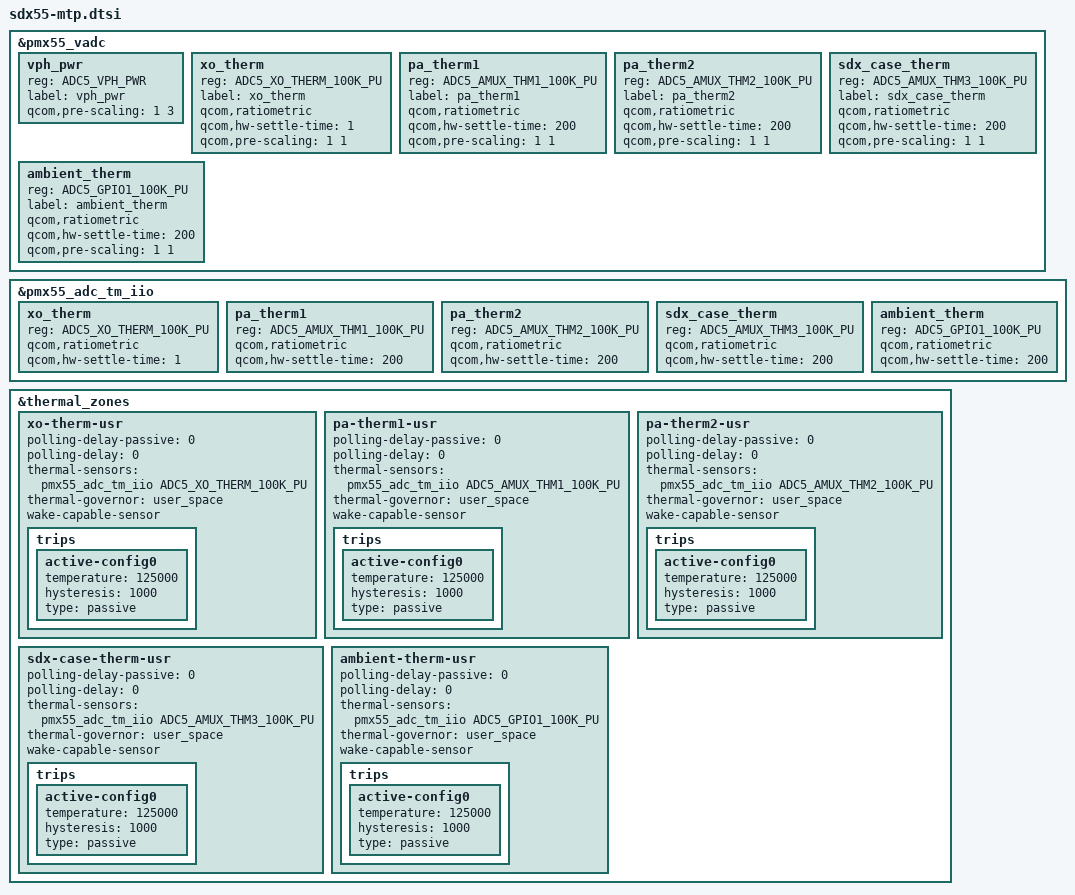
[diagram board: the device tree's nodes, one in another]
#include "sdx55-pmic-overlay.dtsi"
#include "sa515m-mtp-audio-overlay.dtsi"

&pmx55_vadc {
	vph_pwr {
		reg = <ADC5_VPH_PWR>;
		label = "vph_pwr";
		qcom,pre-scaling = <1 3>;
	};

	xo_therm {
		reg = <ADC5_XO_THERM_100K_PU>;
		label = "xo_therm";
		qcom,ratiometric;
		qcom,hw-settle-time = <1>;
		qcom,pre-scaling = <1 1>;
	};

	pa_therm1 {
		reg = <ADC5_AMUX_THM1_100K_PU>;
		label = "pa_therm1";
		qcom,ratiometric;
		qcom,hw-settle-time = <200>;
		qcom,pre-scaling = <1 1>;
	};

	pa_therm2 {
		reg = <ADC5_AMUX_THM2_100K_PU>;
		label = "pa_therm2";
		qcom,ratiometric;
		qcom,hw-settle-time = <200>;
		qcom,pre-scaling = <1 1>;
	};

	sdx_case_therm {
		reg = <ADC5_AMUX_THM3_100K_PU>;
		label = "sdx_case_therm";
		qcom,ratiometric;
		qcom,hw-settle-time = <200>;
		qcom,pre-scaling = <1 1>;
	};

	ambient_therm {
		reg = <ADC5_GPIO1_100K_PU>;
		label = "ambient_therm";
		qcom,ratiometric;
		qcom,hw-settle-time = <200>;
		qcom,pre-scaling = <1 1>;
	};
};

&pmx55_adc_tm_iio {
	xo_therm {
		reg = <ADC5_XO_THERM_100K_PU>;
		qcom,ratiometric;
		qcom,hw-settle-time = <1>;
	};

	pa_therm1 {
		reg = <ADC5_AMUX_THM1_100K_PU>;
		qcom,ratiometric;
		qcom,hw-settle-time = <200>;
	};

	pa_therm2 {
		reg = <ADC5_AMUX_THM2_100K_PU>;
		qcom,ratiometric;
		qcom,hw-settle-time = <200>;
	};

	sdx_case_therm {
		reg = <ADC5_AMUX_THM3_100K_PU>;
		qcom,ratiometric;
		qcom,hw-settle-time = <200>;
	};

	ambient_therm {
		reg = <ADC5_GPIO1_100K_PU>;
		qcom,ratiometric;
		qcom,hw-settle-time = <200>;
	};
};

&thermal_zones {
	xo-therm-usr {
		polling-delay-passive = <0>;
		polling-delay = <0>;
		thermal-sensors = <&pmx55_adc_tm_iio ADC5_XO_THERM_100K_PU>;
		thermal-governor = "user_space";
		wake-capable-sensor;

		trips {
			active-config0 {
				temperature = <125000>;
				hysteresis = <1000>;
				type = "passive";
			};
		};
	};

	pa-therm1-usr {
		polling-delay-passive = <0>;
		polling-delay = <0>;
		thermal-sensors = <&pmx55_adc_tm_iio ADC5_AMUX_THM1_100K_PU>;
		thermal-governor = "user_space";
		wake-capable-sensor;

		trips {
			active-config0 {
				temperature = <125000>;
				hysteresis = <1000>;
				type = "passive";
			};
		};
	};

	pa-therm2-usr {
		polling-delay-passive = <0>;
		polling-delay = <0>;
		thermal-sensors = <&pmx55_adc_tm_iio ADC5_AMUX_THM2_100K_PU>;
		thermal-governor = "user_space";
		wake-capable-sensor;

		trips {
			active-config0 {
				temperature = <125000>;
				hysteresis = <1000>;
				type = "passive";
			};
		};
	};

	sdx-case-therm-usr {
		polling-delay-passive = <0>;
		polling-delay = <0>;
		thermal-sensors = <&pmx55_adc_tm_iio ADC5_AMUX_THM3_100K_PU>;
		thermal-governor = "user_space";
		wake-capable-sensor;

		trips {
			active-config0 {
				temperature = <125000>;
				hysteresis = <1000>;
				type = "passive";
			};
		};
	};

	ambient-therm-usr {
		polling-delay-passive = <0>;
		polling-delay = <0>;
		thermal-sensors = <&pmx55_adc_tm_iio ADC5_GPIO1_100K_PU>;
		thermal-governor = "user_space";
		wake-capable-sensor;

		trips {
			active-config0 {
				temperature = <125000>;
				hysteresis = <1000>;
				type = "passive";
			};
		};
	};
};
